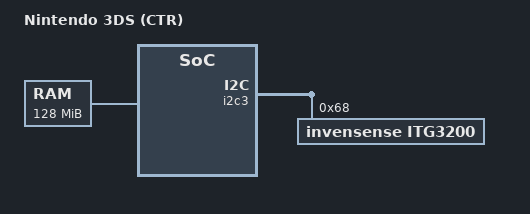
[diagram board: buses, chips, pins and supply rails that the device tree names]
// SPDX-License-Identifier: GPL-2.0
/*
 * Support for:
 *   - Nintendo 3DS    (CTR-001)
 *   - Nintendo 3DS XL (SPR-001)
 *   - Nintendo 2DS    (FTR-001)
 */
/dts-v1/;

#include "nintendo3ds.dtsi"

/ {
	model = "Nintendo 3DS (CTR)";
	compatible = "nintendo,ctr", "nintendo,3ds";

	fcram: memory@20000000 {
		device_type = "memory";
		reg = <0x20000000 0x08000000>;
	};

	cpus {
		#address-cells = <1>;
		#size-cells = <0>;
		enable-method = "nintendo,3ds-smp";

		cpu@0 {
			device_type = "cpu";
			compatible = "arm,arm11mpcore";
			reg = <0>;
		};

		cpu@1 {
			device_type = "cpu";
			compatible = "arm,arm11mpcore";
			reg = <1>;
		};
	};

	chosen {
		bootargs = "keep_bootcon fbcon=rotate:1";
		// At the end of the fcram
		linux,initrd-start = <0x27800000>;
		linux,initrd-end = <0x28000000>; // 8 MiB
	};
};

&i2c3 {
	itg3200: gyroscope@68 {
		compatible = "invensense,itg3200";
		reg = <0x68>;
	};
};
